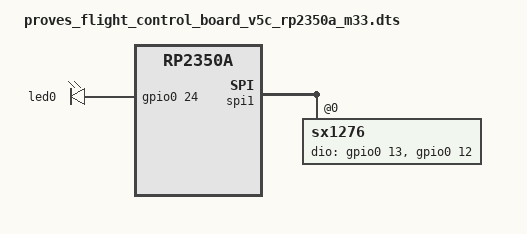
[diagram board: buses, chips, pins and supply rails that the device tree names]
/*
 * Copyright (c) 2024 Andrew Featherstone
 *
 * SPDX-License-Identifier: Apache-2.0
 */

/dts-v1/;

/* The build system assumes that there's a cpucluster-specific file.
 *
 * This file provides composition of the device tree:
 * 1. The common features of the SoC
 * 2. Core-specific configuration.
 * 3. Board-specific configuration.
 */
#include <raspberrypi/rpi_pico/rp2350a.dtsi>
#include <raspberrypi/rpi_pico/m33.dtsi>

#include "../proves_flight_control_board_v5/proves_flight_control_board_v5.dtsi"

// Configure the Watchdog LED
&led0 {
	gpios = <&gpio0 24 GPIO_ACTIVE_HIGH>;
};

// Configure the LoRa DIO pins
&spi1 {
	sx1276@0 {
		dio-gpios =  <&gpio0 13 (GPIO_PULL_DOWN | GPIO_ACTIVE_HIGH)>,<&gpio0 12 (GPIO_PULL_DOWN | GPIO_ACTIVE_HIGH)>;
	};
};
